# CY8C5888LTI_LP097 register map
File version: 0.1
Registers are 8-bit, read-write, no defined reset value unless marked. A register's access mark holds for its fields unless they carry their own. Offsets are from the block's base; [hi:lo] are bit positions.

## XBee — UART
Base 0x00000000
0x40006425 RX_XBee_RX_ADDRESS1 — RX Address1 Register
0x40006435 RX_XBee_RX_ADDRESS2 — RX Address2 Register
0x40006445 RX_XBee_RX_DATA — RX Data Register
0x4000644E TX_XBee_TX_DATA — TX Data Register
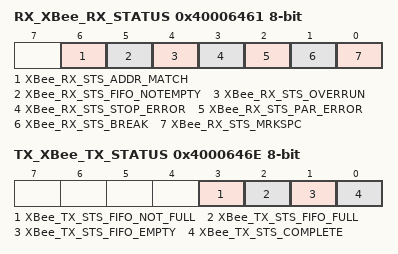
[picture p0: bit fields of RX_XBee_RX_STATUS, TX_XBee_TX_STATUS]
0x40006461 RX_XBee_RX_STATUS — RX status register
  [6] XBee_RX_STS_ADDR_MATCH ro, [5] XBee_RX_STS_FIFO_NOTEMPTY ro, [4] XBee_RX_STS_OVERRUN ro, [3] XBee_RX_STS_STOP_ERROR ro, [2] XBee_RX_STS_PAR_ERROR ro, [1] XBee_RX_STS_BREAK ro, [0] XBee_RX_STS_MRKSPC ro
0x4000646E TX_XBee_TX_STATUS — TX status register
  [3] XBee_TX_STS_FIFO_NOT_FULL ro, [2] XBee_TX_STS_FIFO_FULL ro, [1] XBee_TX_STS_FIFO_EMPTY ro, [0] XBee_TX_STS_COMPLETE ro

## GSM — UART
Base 0x00000000
0x40006422 RX_GSM_RX_ADDRESS1 — RX Address1 Register
0x40006432 RX_GSM_RX_ADDRESS2 — RX Address2 Register
0x40006442 RX_GSM_RX_DATA — RX Data Register
0x40006447 TX_GSM_TX_DATA — TX Data Register
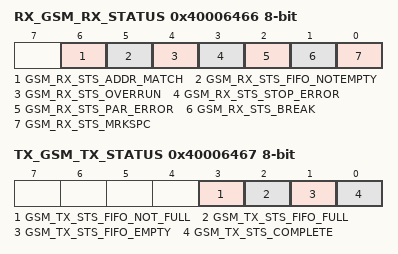
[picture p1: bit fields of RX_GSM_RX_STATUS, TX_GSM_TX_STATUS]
0x40006466 RX_GSM_RX_STATUS — RX status register
  [6] GSM_RX_STS_ADDR_MATCH ro, [5] GSM_RX_STS_FIFO_NOTEMPTY ro, [4] GSM_RX_STS_OVERRUN ro, [3] GSM_RX_STS_STOP_ERROR ro, [2] GSM_RX_STS_PAR_ERROR ro, [1] GSM_RX_STS_BREAK ro, [0] GSM_RX_STS_MRKSPC ro
0x40006467 TX_GSM_TX_STATUS — TX status register
  [3] GSM_TX_STS_FIFO_NOT_FULL ro, [2] GSM_TX_STS_FIFO_FULL ro, [1] GSM_TX_STS_FIFO_EMPTY ro, [0] GSM_TX_STS_COMPLETE ro

## LCD1 — UART
Base 0x00000000
0x40006423 RX_LCD1_RX_ADDRESS1 — RX Address1 Register
0x40006433 RX_LCD1_RX_ADDRESS2 — RX Address2 Register
0x40006443 RX_LCD1_RX_DATA — RX Data Register
0x40006448 TX_LCD1_TX_DATA — TX Data Register
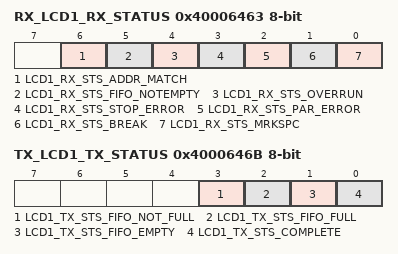
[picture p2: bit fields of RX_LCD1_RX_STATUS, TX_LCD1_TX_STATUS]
0x40006463 RX_LCD1_RX_STATUS — RX status register
  [6] LCD1_RX_STS_ADDR_MATCH ro, [5] LCD1_RX_STS_FIFO_NOTEMPTY ro, [4] LCD1_RX_STS_OVERRUN ro, [3] LCD1_RX_STS_STOP_ERROR ro, [2] LCD1_RX_STS_PAR_ERROR ro, [1] LCD1_RX_STS_BREAK ro, [0] LCD1_RX_STS_MRKSPC ro
0x4000646B TX_LCD1_TX_STATUS — TX status register
  [3] LCD1_TX_STS_FIFO_NOT_FULL ro, [2] LCD1_TX_STS_FIFO_FULL ro, [1] LCD1_TX_STS_FIFO_EMPTY ro, [0] LCD1_TX_STS_COMPLETE ro

## LCD2 — UART
Base 0x00000000
0x40006429 RX_LCD2_RX_ADDRESS1 — RX Address1 Register
0x40006439 RX_LCD2_RX_ADDRESS2 — RX Address2 Register
0x40006446 TX_LCD2_TX_DATA — TX Data Register
0x40006449 RX_LCD2_RX_DATA — RX Data Register
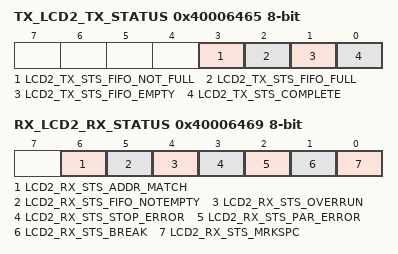
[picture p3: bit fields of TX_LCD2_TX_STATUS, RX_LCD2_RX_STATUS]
0x40006465 TX_LCD2_TX_STATUS — TX status register
  [3] LCD2_TX_STS_FIFO_NOT_FULL ro, [2] LCD2_TX_STS_FIFO_FULL ro, [1] LCD2_TX_STS_FIFO_EMPTY ro, [0] LCD2_TX_STS_COMPLETE ro
0x40006469 RX_LCD2_RX_STATUS — RX status register
  [6] LCD2_RX_STS_ADDR_MATCH ro, [5] LCD2_RX_STS_FIFO_NOTEMPTY ro, [4] LCD2_RX_STS_OVERRUN ro, [3] LCD2_RX_STS_STOP_ERROR ro, [2] LCD2_RX_STS_PAR_ERROR ro, [1] LCD2_RX_STS_BREAK ro, [0] LCD2_RX_STS_MRKSPC ro

## WIFI — UART
Base 0x00000000
0x4000644C TX_WIFI_TX_DATA — TX Data Register
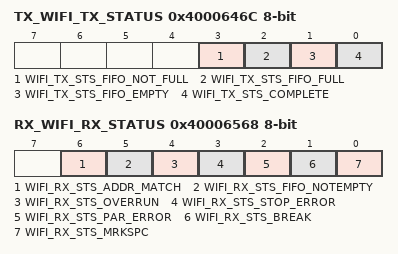
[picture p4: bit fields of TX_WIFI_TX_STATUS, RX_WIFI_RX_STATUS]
0x4000646C TX_WIFI_TX_STATUS — TX status register
  [3] WIFI_TX_STS_FIFO_NOT_FULL ro, [2] WIFI_TX_STS_FIFO_FULL ro, [1] WIFI_TX_STS_FIFO_EMPTY ro, [0] WIFI_TX_STS_COMPLETE ro
0x4000652A RX_WIFI_RX_ADDRESS1 — RX Address1 Register
0x4000653A RX_WIFI_RX_ADDRESS2 — RX Address2 Register
0x4000654A RX_WIFI_RX_DATA — RX Data Register
0x40006568 RX_WIFI_RX_STATUS — RX status register
  [6] WIFI_RX_STS_ADDR_MATCH ro, [5] WIFI_RX_STS_FIFO_NOTEMPTY ro, [4] WIFI_RX_STS_OVERRUN ro, [3] WIFI_RX_STS_STOP_ERROR ro, [2] WIFI_RX_STS_PAR_ERROR ro, [1] WIFI_RX_STS_BREAK ro, [0] WIFI_RX_STS_MRKSPC ro

## PSOC — UART
Base 0x00000000
0x4000642A RX_PSOC_RX_ADDRESS1 — RX Address1 Register
0x4000643A RX_PSOC_RX_ADDRESS2 — RX Address2 Register
0x4000644A RX_PSOC_RX_DATA — RX Data Register
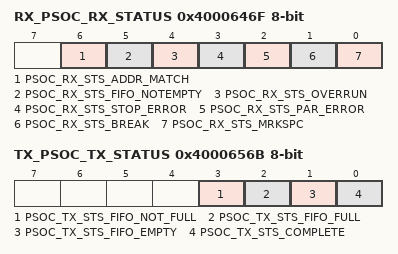
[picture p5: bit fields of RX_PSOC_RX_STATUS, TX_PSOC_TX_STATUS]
0x4000646F RX_PSOC_RX_STATUS — RX status register
  [6] PSOC_RX_STS_ADDR_MATCH ro, [5] PSOC_RX_STS_FIFO_NOTEMPTY ro, [4] PSOC_RX_STS_OVERRUN ro, [3] PSOC_RX_STS_STOP_ERROR ro, [2] PSOC_RX_STS_PAR_ERROR ro, [1] PSOC_RX_STS_BREAK ro, [0] PSOC_RX_STS_MRKSPC ro
0x4000654B TX_PSOC_TX_DATA — TX Data Register
0x4000656B TX_PSOC_TX_STATUS — TX status register
  [3] PSOC_TX_STS_FIFO_NOT_FULL ro, [2] PSOC_TX_STS_FIFO_FULL ro, [1] PSOC_TX_STS_FIFO_EMPTY ro, [0] PSOC_TX_STS_COMPLETE ro
